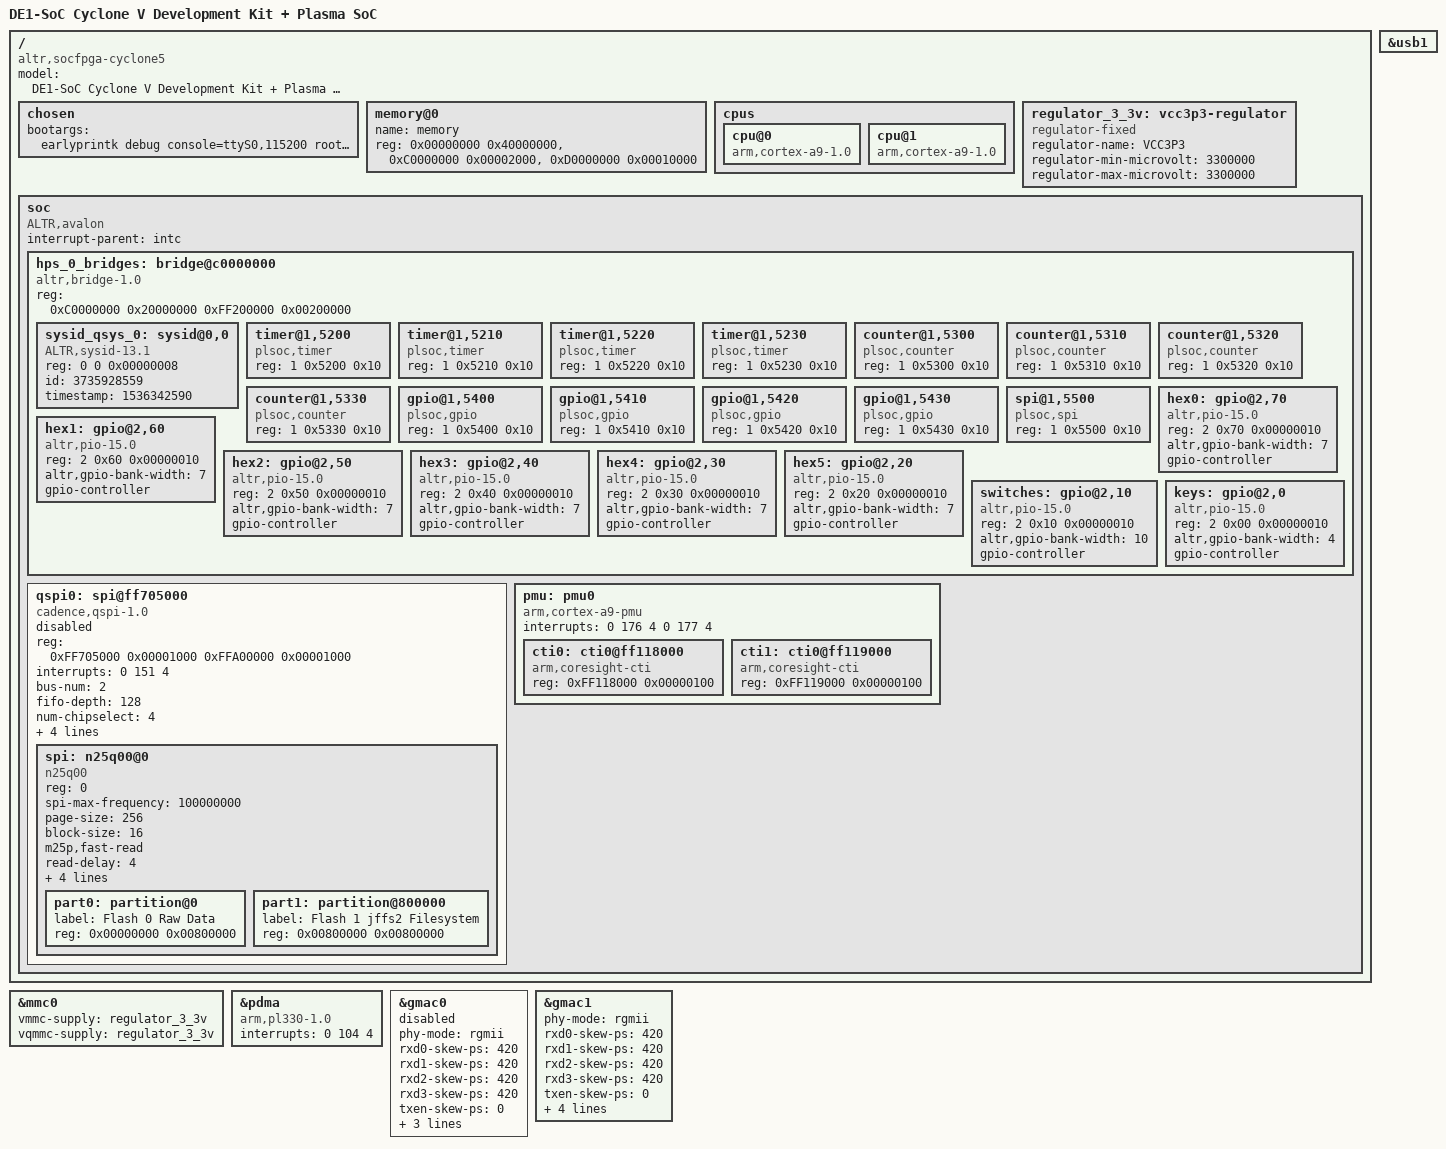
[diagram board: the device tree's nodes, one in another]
/dts-v1/;

#include "socfpga_cyclone5.dtsi"
#include <dt-bindings/reset/altr,rst-mgr.h>

/ {

    model = "DE1-SoC Cyclone V Development Kit + Plasma SoC";
	compatible = "altr,socfpga-cyclone5", "altr,socfpga";


    chosen {
		bootargs = "earlyprintk debug console=ttyS0,115200 root=/dev/mmcblk0p2 rw rootwait mem=768M";
	};

	memory@0 {
		name = "memory";
		device_type = "memory";
		reg = <0x00000000 0x40000000>, 	/* 1GB DDR3 */
			<0xC0000000 0x00002000>,  	/* 8KB Plasma RAM0 */
			<0xD0000000 0x00010000>; 	/* 64MB Plasma RAM1 */
	};

    cpus {
		cpu@0 {
			compatible = "arm,cortex-a9-1.0", "arm,cortex-a9";
		};
		cpu@1 {
			compatible = "arm,cortex-a9-1.0", "arm,cortex-a9";
		};
	};

	regulator_3_3v: vcc3p3-regulator {
		compatible = "regulator-fixed";
		regulator-name = "VCC3P3";
		regulator-min-microvolt = <3300000>;
		regulator-max-microvolt = <3300000>;
	};

	soc {		
        device_type = "soc";
		ranges;
		#address-cells = < 1 >;
		#size-cells = < 1 >;
		compatible = "ALTR,avalon", "simple-bus";
		interrupt-parent = < &intc >;

		hps_0_bridges: bridge@c0000000 {
			compatible = "altr,bridge-1.0", "simple-bus";
			reg = < 0xC0000000 0x20000000 0xFF200000 0x00200000 >;
			reg-names = "axi_h2f", "axi_h2f_lw";
			#address-cells = < 2 >;
			#size-cells = < 1 >;
			ranges = < 0 0 0xFF200000 0x00000008 >,
					 < 1 0 0xC0000000 0x00005510 >,
					 < 2 0 0xD4000000 0x00000080 >;


			sysid_qsys_0: sysid@0,0 {
				compatible = "ALTR,sysid-13.1", "ALTR,sysid-1.0", "altr,sysid-1.0";
				reg = <0 0 0x00000008>;
				id = < 3735928559 >;
				timestamp = < 1536342590 >;
			}; 
		
			timer@1,5200 {
				compatible = "plsoc,timer";
				reg = <1 0x5200 0x10>;
			};

			timer@1,5210 {
				compatible = "plsoc,timer";
				reg = <1 0x5210 0x10>;
			};

			timer@1,5220 {
				compatible = "plsoc,timer";
				reg = <1 0x5220 0x10>;
			};

			timer@1,5230 {
				compatible = "plsoc,timer";
				reg = <1 0x5230 0x10>;
			};	

			counter@1,5300 {
				compatible = "plsoc,counter";
				reg = <1 0x5300 0x10>;
			};

			counter@1,5310 {
				compatible = "plsoc,counter";
				reg = <1 0x5310 0x10>;
			};

			counter@1,5320 {
				compatible = "plsoc,counter";
				reg = <1 0x5320 0x10>;
			};

			counter@1,5330 {
				compatible = "plsoc,counter";
				reg = <1 0x5330 0x10>;
			};

			gpio@1,5400 {
				compatible = "plsoc,gpio";
				reg = <1 0x5400 0x10>;
			};

			gpio@1,5410 {
				compatible = "plsoc,gpio";
				reg = <1 0x5410 0x10>;
			};

			gpio@1,5420 {
				compatible = "plsoc,gpio";
				reg = <1 0x5420 0x10>;
			};

			gpio@1,5430 {
				compatible = "plsoc,gpio";
				reg = <1 0x5430 0x10>;
			};

			spi@1,5500 {
				compatible = "plsoc,spi";
				reg = <1 0x5500 0x10>;
			};

			// plasma RAM1
			// -----------
			hex0: gpio@2,70 {
				compatible = "altr,pio-15.0", "altr,pio-1.0";
				reg = <2 0x70 0x00000010>;
				altr,gpio-bank-width = <7>;		
				#gpio-cells = <1>;
				gpio-controller;			
			};

			hex1: gpio@2,60 {
				compatible = "altr,pio-15.0", "altr,pio-1.0";
				reg = <2 0x60 0x00000010>;
				altr,gpio-bank-width = <7>;		
				#gpio-cells = <1>;
				gpio-controller;				
			};

			hex2: gpio@2,50 {
				compatible = "altr,pio-15.0", "altr,pio-1.0";
				reg = <2 0x50 0x00000010>;	
				altr,gpio-bank-width = <7>;		
				#gpio-cells = <1>;
				gpio-controller;					
			};

			hex3: gpio@2,40 {
				compatible = "altr,pio-15.0", "altr,pio-1.0";
				reg = <2 0x40 0x00000010>;	
				altr,gpio-bank-width = <7>;		
				#gpio-cells = <1>;
				gpio-controller;					
			};

			hex4: gpio@2,30 {
				compatible = "altr,pio-15.0", "altr,pio-1.0";
				reg = <2 0x30 0x00000010>;		
				altr,gpio-bank-width = <7>;		
				#gpio-cells = <1>;
				gpio-controller;				
			};

			hex5: gpio@2,20 {
				compatible = "altr,pio-15.0", "altr,pio-1.0";
				reg = <2 0x20 0x00000010>;	
				altr,gpio-bank-width = <7>;		
				#gpio-cells = <1>;
				gpio-controller;					
			};
			
			switches: gpio@2,10 {
				compatible = "altr,pio-15.0", "altr,pio-1.0";
				reg = <2 0x10 0x00000010>;							
				altr,gpio-bank-width = <10>;
				// TODO:
				// altr,interrupt_type = <IRQ_TYPE_EDGE_BOTH>;	
				// interrupts = <0 41 1>;	
				// #interrupt-cells = <1>;
				// interrupt-controller;	
				#gpio-cells = <1>;
				gpio-controller;			
			};

			keys: gpio@2,0 {
				compatible = "altr,pio-15.0", "altr,pio-1.0";
				reg = <2 0x00 0x00000010>;
				altr,gpio-bank-width = <4>;		
				// TODO:
				// altr,interrupt_type = <IRQ_TYPE_EDGE_FALLING>;
				// interrupts = <0 41 1>;
				// #interrupt-cells = <1>;
				// interrupt-controller;
				#gpio-cells = <1>;						
				gpio-controller;				
			};
		}; 

        qspi0: spi@ff705000 {
			compatible = "cadence,qspi-1.0", "cadence,qspi";
			reg = < 0xFF705000 0x00001000 
				0xFFA00000 0x00001000 >;
			reg-names = "axi_slave0", "axi_slave1";
			interrupts = < 0 151 4 >;
			bus-num = < 2 >;
			fifo-depth = < 128 >;
			num-chipselect = < 4 >;
			bank-width = < 2 >;
			device-width = < 1 >;
			master-ref-clk = < 400000000 >;
			ext-decoder = < 0 >;
			#address-cells = < 1 >;
			#size-cells = < 0 >;

            status = "disabled";

			spi: n25q00@0 {
				#address-cells = < 1 >;
				#size-cells = < 1 >;
				compatible = "n25q00";
				reg = < 0 >;
				spi-max-frequency = < 100000000 >;
				page-size = < 256 >;
				block-size = < 16 >;
				m25p,fast-read;
				read-delay = < 4 >;
				tshsl-ns = < 50 >;
				tsd2d-ns = < 50 >;
				tchsh-ns = < 4 >;
				tslch-ns = < 4 >;

				part0: partition@0 {
					label = "Flash 0 Raw Data";
					reg = < 0x00000000 0x00800000 >;
				};

				part1: partition@800000 {
					label = "Flash 1 jffs2 Filesystem";
					reg = < 0x00800000 0x00800000 >;
				};
			};
		};

        pmu: pmu0 {
			#address-cells = < 1 >;
			#size-cells = < 1 >;
			compatible = "arm,cortex-a9-pmu";
			interrupts = < 0 176 4 0 177 4 >;
			ranges;

			cti0: cti0@ff118000 {
				compatible = "arm,coresight-cti";
				reg = < 0xFF118000 0x00000100 >;
			}; 

			cti1: cti0@ff119000 {
				compatible = "arm,coresight-cti";
				reg = < 0xFF119000 0x00000100 >;
			};
		};
	};
};

&mmc0 {
    vmmc-supply = <&regulator_3_3v>;
    vqmmc-supply = <&regulator_3_3v>;
	status = "okay";
};

&pdma {
    compatible = "arm,pl330-1.0", "arm,pl330", "arm,primecell";
    interrupts = < 0 104 4 >;
	status = "okay";
};

&usb1 {	
   status = "okay";
};

&gmac0 {
	phy-mode = "rgmii";
	rxd0-skew-ps = <420>;
	rxd1-skew-ps = <420>;
	rxd2-skew-ps = <420>;
	rxd3-skew-ps = <420>;
	txen-skew-ps = <0>;
	txc-skew-ps = <1860>;
	rxdv-skew-ps = <420>;
	rxc-skew-ps = <1680>;
	
	//mac-address = [32 C1 26 B4 4C 59];

    status = "disabled";
};

&gmac1 {
	phy-mode = "rgmii";
	rxd0-skew-ps = <420>;
	rxd1-skew-ps = <420>;
	rxd2-skew-ps = <420>;
	rxd3-skew-ps = <420>;
	txen-skew-ps = <0>;
	txc-skew-ps = <1860>;
	rxdv-skew-ps = <420>;
	rxc-skew-ps = <1680>;

	mac-address = [00 DE AD BE EF 00];

    status = "okay";
};
